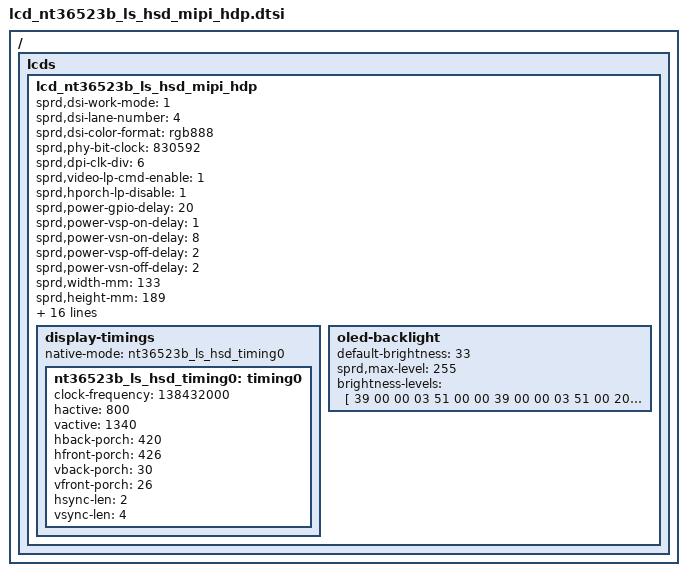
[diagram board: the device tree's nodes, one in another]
/**
*Name：<lcd_nt36523b_ls_hsd_mipi_hdp>
*Author：<huangzhongjie>
*Date：<2022/01/12>
*Purpose：<Tab A7 T168 LCD bring up>
*/
/ {
    fragment {
        target-path = "/";
        __overlay__ {
            lcds {
                lcd_nt36523b_ls_hsd_mipi_hdp: lcd_nt36523b_ls_hsd_mipi_hdp {

                    sprd,dsi-work-mode = <1>; /* video burst mode*/
                    sprd,dsi-lane-number = <4>;
                    sprd,dsi-color-format = "rgb888";

                    sprd,phy-bit-clock = <830592>;    /* kbps */
                    sprd,dpi-clk-div = <6>;
                    sprd,video-lp-cmd-enable = <1>;
                    sprd,hporch-lp-disable = <1>;
                    sprd,power-gpio-delay = <20>;/* ms */
                    sprd,power-vsp-on-delay = <1>;
                    sprd,power-vsn-on-delay = <8>;
                    sprd,power-vsp-off-delay = <2>;
                    sprd,power-vsn-off-delay = <2>;

                    sprd,width-mm = <133>;
                    sprd,height-mm = <189>;

                    sprd,reset-on-sequence = <1 10>, <0 5>, <1 5>, <0 5>, <1 10>;
                    sprd,reset-off-sequence = <1 5>;

                    sprd,esd-check-enable = <1>;
                    sprd,esd-check-mode = <0>;
                    sprd,esd-check-reg-count = <2>;
                    sprd,esd-check-register = [0A AB];
                    sprd,esd-check-value-len = <1 2>;
                    sprd,esd-check-value = [9C 00 00];
                    sprd,esd-check-period = <2000>;

                    sprd,initial-command = [
                        39 00 00 02 FF 20
                        39 00 00 02 FB 01
                        39 00 00 02 05 B1
                        39 00 00 02 06 C0
                        39 00 00 02 07 69
                        39 00 00 02 08 37
                        39 00 00 02 0D 63
                        39 00 00 02 0E 87
                        39 00 00 02 0F 55
                        39 00 00 02 58 60
                        39 00 00 02 69 90
                        39 00 00 02 75 30
                        39 00 00 02 77 B3
                        39 00 00 02 94 C0
                        39 00 00 02 95 09
                        39 00 00 02 96 09
                        39 00 00 02 FF 20
                        39 00 00 02 FB 01
                        39 00 00 11 B0 00 65 00 73 00 8E 00 A5 00 B9 00 CC 00 DD 00 EC
                        39 00 00 11 B1 00 FB 01 2C 01 51 01 8F 01 BB 02 05 02 3E 02 3F
                        39 00 00 11 B2 02 78 02 BB 02 EB 03 23 03 48 03 73 03 81 03 8F
                        39 00 00 0D B3 03 9E 03 AE 03 BD 03 CA 03 D1 03 D2
                        39 00 00 11 B4 00 65 00 73 00 8E 00 A5 00 B9 00 CC 00 DD 00 EC
                        39 00 00 11 B5 00 FB 01 2C 01 51 01 8F 01 BB 02 05 02 3E 02 3F
                        39 00 00 11 B6 02 78 02 BB 02 EB 03 23 03 48 03 73 03 81 03 8F
                        39 00 00 0D B7 03 9E 03 AE 03 BD 03 CA 03 D1 03 D2
                        39 00 00 11 B8 00 65 00 73 00 8E 00 A5 00 B9 00 CC 00 DD 00 EC
                        39 00 00 11 B9 00 FB 01 2C 01 51 01 8F 01 BB 02 05 02 3E 02 3F
                        39 00 00 11 BA 02 78 02 BB 02 EB 03 23 03 48 03 73 03 81 03 8F
                        39 00 00 0D BB 03 9E 03 AE 03 BD 03 CA 03 D1 03 D2
                        39 00 00 02 FF 21
                        39 00 00 02 FB 01
                        39 00 00 11 B0 00 5D 00 6B 00 86 00 9D 00 B1 00 C4 00 D5 00 E4
                        39 00 00 11 B1 00 F3 01 24 01 49 01 87 01 B3 01 FD 02 36 02 37
                        39 00 00 11 B2 02 70 02 B3 02 E3 03 1B 03 40 03 6B 03 79 03 87
                        39 00 00 0D B3 03 96 03 A6 03 B5 03 C2 03 C9 03 CA
                        39 00 00 11 B4 00 5D 00 6B 00 86 00 9D 00 B1 00 C4 00 D5 00 E4
                        39 00 00 11 B5 00 F3 01 24 01 49 01 87 01 B3 01 FD 02 36 02 37
                        39 00 00 11 B6 02 70 02 B3 02 E3 03 1B 03 40 03 6B 03 79 03 87
                        39 00 00 0D B7 03 96 03 A6 03 B5 03 C2 03 C9 03 CA
                        39 00 00 11 B8 00 5D 00 6B 00 86 00 9D 00 B1 00 C4 00 D5 00 E4
                        39 00 00 11 B9 00 F3 01 24 01 49 01 87 01 B3 01 FD 02 36 02 37
                        39 00 00 11 BA 02 70 02 B3 02 E3 03 1B 03 40 03 6B 03 79 03 87
                        39 00 00 0D BB 03 96 03 A6 03 B5 03 C2 03 C9 03 CA
                        39 00 00 02 FF 23
                        39 00 00 02 FB 01
                        39 00 00 02 00 80
                        39 00 00 02 07 00
                        39 00 00 02 08 02
                        39 00 00 02 09 00
                        39 00 00 02 11 00
                        39 00 00 02 12 A8
                        39 00 00 02 15 7D
                        39 00 00 02 16 0A
                        39 00 00 02 FF 24
                        39 00 00 02 FB 01
                        39 00 00 02 60 C8
                        39 00 00 02 61 3C
                        39 00 00 02 63 50
                        39 00 00 02 91 20
                        39 00 00 02 92 2F
                        39 00 00 02 93 1A
                        39 00 00 02 94 08
                        39 00 00 02 C2 CA
                        39 00 00 02 00 00
                        39 00 00 02 01 00
                        39 00 00 02 02 00
                        39 00 00 02 03 00
                        39 00 00 02 04 00
                        39 00 00 02 05 22
                        39 00 00 02 06 23
                        39 00 00 02 07 1C
                        39 00 00 02 08 1D
                        39 00 00 02 09 0C
                        39 00 00 02 0A 0D
                        39 00 00 02 0B 0E
                        39 00 00 02 0C 0F
                        39 00 00 02 0D 04
                        39 00 00 02 0E 05
                        39 00 00 02 0F 00
                        39 00 00 02 10 00
                        39 00 00 02 11 00
                        39 00 00 02 12 00
                        39 00 00 02 13 00
                        39 00 00 02 14 00
                        39 00 00 02 15 00
                        39 00 00 02 16 00
                        39 00 00 02 17 00
                        39 00 00 02 18 00
                        39 00 00 02 19 00
                        39 00 00 02 1A 00
                        39 00 00 02 1B 22
                        39 00 00 02 1C 23
                        39 00 00 02 1D 1C
                        39 00 00 02 1E 1D
                        39 00 00 02 1F 0C
                        39 00 00 02 20 0D
                        39 00 00 02 21 0E
                        39 00 00 02 22 0F
                        39 00 00 02 23 04
                        39 00 00 02 24 05
                        39 00 00 02 25 00
                        39 00 00 02 26 00
                        39 00 00 02 27 00
                        39 00 00 02 28 00
                        39 00 00 02 29 00
                        39 00 00 02 2A 00
                        39 00 00 02 2B 00
                        39 00 00 02 2F 02
                        39 00 00 02 30 41
                        39 00 00 02 33 41
                        39 00 00 02 34 02
                        39 00 00 02 37 22
                        39 00 00 02 39 01
                        39 00 00 02 3A 05
                        39 00 00 02 3B 2A
                        39 00 00 02 3D 52
                        39 00 00 02 AB 22
                        39 00 00 02 4D 21
                        39 00 00 02 4E 43
                        39 00 00 02 51 12
                        39 00 00 02 52 34
                        39 00 00 03 55 41 01
                        39 00 00 02 56 04
                        39 00 00 02 58 21
                        39 00 00 02 59 21
                        39 00 00 02 5A 05
                        39 00 00 02 5B 20
                        39 00 00 02 5C 00
                        39 00 00 02 5D 00
                        39 00 00 03 5E 00 00
                        39 00 00 02 5F 00
                        39 00 00 02 65 C2
                        39 00 00 02 7A 00
                        39 00 00 02 7B 00
                        39 00 00 02 7E 20
                        39 00 00 02 7F 3C
                        39 00 00 02 80 50
                        39 00 00 02 82 88
                        39 00 00 02 97 C2
                        39 00 00 02 C3 00
                        39 00 00 02 C4 20
                        39 00 00 02 DB F2
                        39 00 00 02 DC 2D
                        39 00 00 02 DF 82
                        39 00 00 02 E0 2D
                        39 00 00 02 E1 82
                        39 00 00 02 E2 2D
                        39 00 00 02 E3 82
                        39 00 00 02 E4 2D
                        39 00 00 02 E5 82
                        39 00 00 02 E6 2D
                        39 00 00 02 E7 00
                        39 00 00 02 E8 00
                        39 00 00 02 E9 82
                        39 00 00 02 EA 2D
                        39 00 00 02 EB 82
                        39 00 00 02 EE 2D
                        39 00 00 02 EF 82
                        39 00 00 02 F0 2D
                        39 00 00 02 B5 90
                        39 00 00 0D B6 05 00 05 00 00 00 00 00 05 05 00 00
                        39 00 00 02 FF 25
                        39 00 00 02 FB 01
                        39 00 00 02 05 04
                        39 00 00 02 13 04
                        39 00 00 02 14 77
                        39 00 00 02 19 07
                        39 00 00 02 1B 11
                        39 00 00 02 1E 00
                        39 00 00 02 1F 05
                        39 00 00 02 20 BB
                        39 00 00 02 25 04
                        39 00 00 02 26 05
                        39 00 00 02 27 20
                        39 00 00 02 3F 00
                        39 00 00 02 43 44
                        39 00 00 02 44 05
                        39 00 00 02 45 2A
                        39 00 00 02 48 05
                        39 00 00 02 49 20
                        39 00 00 02 5C 44
                        39 00 00 02 5D 05
                        39 00 00 02 5E 2A
                        39 00 00 02 61 05
                        39 00 00 02 62 20
                        39 00 00 02 FF 26
                        39 00 00 02 FB 01
                        39 00 00 02 00 A1
                        39 00 00 02 04 28
                        39 00 00 02 06 30
                        39 00 00 02 0C 11
                        39 00 00 02 0D 00
                        39 00 00 02 0F 09
                        39 00 00 02 11 00
                        39 00 00 02 12 50
                        39 00 00 02 13 49
                        39 00 00 02 14 49
                        39 00 00 02 15 00
                        39 00 00 02 16 90
                        39 00 00 02 17 A0
                        39 00 00 02 18 86
                        39 00 00 02 19 11
                        39 00 00 02 1A 00
                        39 00 00 02 1B 0E
                        39 00 00 02 1C E0
                        39 00 00 02 22 00
                        39 00 00 02 23 00
                        39 00 00 02 2A 0F
                        39 00 00 02 2B A0
                        39 00 00 02 1D C0
                        39 00 00 02 1E 2F
                        39 00 00 02 1F 2F
                        39 00 00 02 20 00
                        39 00 00 02 21 07
                        39 00 00 02 2F 86
                        39 00 00 02 30 2F
                        39 00 00 02 33 66
                        39 00 00 02 34 66
                        39 00 00 02 35 66
                        39 00 00 02 39 85
                        39 00 00 02 3A 2F
                        39 00 00 02 3B 00
                        39 00 00 02 C8 04
                        39 00 00 02 C9 15
                        39 00 00 02 CA 4E
                        39 00 00 02 CB 00
                        39 00 00 02 A9 63
                        39 00 00 02 AA 67
                        39 00 00 02 AB 6B
                        39 00 00 02 AC 59
                        39 00 00 02 AD 6E
                        39 00 00 02 AE 6A
                        39 00 00 02 AF 62
                        39 00 00 02 B0 5C
                        39 00 00 02 B1 69
                        39 00 00 02 B2 5E
                        39 00 00 02 B3 64
                        39 00 00 02 B4 68
                        39 00 00 02 B5 61
                        39 00 00 02 B6 58
                        39 00 00 02 B7 5B
                        39 00 00 02 B8 5F
                        39 00 00 02 B9 65
                        39 00 00 02 BA 66
                        39 00 00 02 BB 6C
                        39 00 00 02 BC 6D
                        39 00 00 02 FF 27
                        39 00 00 02 FB 01
                        39 00 00 02 00 00
                        39 00 00 02 C3 00
                        39 00 00 02 58 00
                        39 00 00 02 78 00
                        39 00 00 02 FF 2A
                        39 00 00 02 FB 01
                        39 00 00 02 64 16
                        39 00 00 02 6A 16
                        39 00 00 02 70 16
                        39 00 00 02 79 16
                        39 00 00 02 7C 16
                        39 00 00 02 97 3C
                        39 00 00 02 98 02
                        39 00 00 02 99 95
                        39 00 00 02 9A 06
                        39 00 00 02 9B 00
                        39 00 00 02 9C 0B
                        39 00 00 02 9D 0A
                        39 00 00 02 9E 90
                        39 00 00 02 A2 33
                        39 00 00 02 A3 F0
                        39 00 00 02 A4 C0
                        39 00 00 02 22 00
                        39 00 00 02 23 08
                        39 00 00 02 24 20
                        39 00 00 02 25 2F
                        39 00 00 02 26 F8
                        39 00 00 02 27 00
                        39 00 00 02 28 1A
                        39 00 00 02 29 00
                        39 00 00 02 2A 1A
                        39 00 00 02 2B 00
                        39 00 00 02 2D 1A
                        39 00 00 02 E8 00
                        39 00 00 02 FF F0
                        39 00 00 02 FB 01
                        39 00 00 02 3A 08
                        39 00 00 02 FF 24
                        39 00 00 02 FB 01
                        39 00 00 02 39 00
                        39 00 00 02 3A 03
                        39 00 00 02 3B B0
                        39 00 00 02 49 00
                        39 00 00 02 4A 03
                        39 00 00 02 4B B0
                        39 00 00 02 59 20
                        39 00 00 02 5A 03
                        39 00 00 02 5B AC
                        39 00 00 02 5C 00
                        39 00 00 02 5D 00
                        39 00 00 02 8D 00
                        39 00 00 02 8E 00
                        39 00 00 02 91 04
                        39 00 00 02 92 B2
                        39 00 00 02 DB 71
                        39 00 00 02 DC B1
                        39 00 00 02 DD 11
                        39 00 00 02 DE 27
                        39 00 00 02 DF 01
                        39 00 00 02 E0 B4
                        39 00 00 02 E1 01
                        39 00 00 02 E2 B4
                        39 00 00 02 E3 01
                        39 00 00 02 E4 B4
                        39 00 00 02 E5 01
                        39 00 00 02 E6 B4
                        39 00 00 02 EF 01
                        39 00 00 02 F0 B4
                        39 00 00 02 FF 25
                        39 00 00 02 FB 01
                        39 00 00 02 1E 00
                        39 00 00 02 1F 03
                        39 00 00 02 20 70
                        39 00 00 02 25 00
                        39 00 00 02 26 03
                        39 00 00 02 27 AC
                        39 00 00 02 32 00
                        39 00 00 02 33 03
                        39 00 00 02 34 AC
                        39 00 00 02 43 00
                        39 00 00 02 44 03
                        39 00 00 02 45 B2
                        39 00 00 02 46 03
                        39 00 00 02 47 B2
                        39 00 00 02 48 03
                        39 00 00 02 49 AC
                        39 00 00 02 5C 00
                        39 00 00 02 5D 03
                        39 00 00 02 5E B2
                        39 00 00 02 5F 03
                        39 00 00 02 60 B2
                        39 00 00 02 61 03
                        39 00 00 02 62 AC
                        39 00 00 02 FF 26
                        39 00 00 02 FB 01
                        39 00 00 02 02 31
                        39 00 00 02 19 0A
                        39 00 00 02 1A 33
                        39 00 00 02 1B 09
                        39 00 00 02 1C 13
                        39 00 00 02 2A 09
                        39 00 00 02 2B 60
                        39 00 00 02 1D 00
                        39 00 00 02 1E B5
                        39 00 00 02 1F B5
                        39 00 00 02 24 00
                        39 00 00 02 25 B5
                        39 00 00 02 2F 06
                        39 00 00 02 30 B5
                        39 00 00 02 31 06
                        39 00 00 02 32 CD
                        39 00 00 02 39 05
                        39 00 00 02 3A B5
                        39 00 00 02 FF 2A
                        39 00 00 02 FB 01
                        39 00 00 02 24 00
                        39 00 00 02 25 B2
                        39 00 00 02 FF 10
                        39 00 00 02 FB 01
                        39 00 00 06 3B 03 22 1A 04 04
                        39 00 00 03 68 04 01
                        39 00 00 03 51 00 00
                        39 00 00 02 53 2C
                        39 00 00 02 55 00
                        39 00 00 02 35 00
                        39 78 00 01 11
                        39 14 00 01 29
                    ];

                    sprd,sleep-in-command = [
                        39 00 00 02 FF 10
                        05 32 00 01 28
                        05 78 00 01 10
                    ];

                    sprd,sleep-out-command = [
                        23 64 00 23 11 00
                        23 05 00 23 29 00
                    ];


                    display-timings {
                        native-mode = <&nt36523b_ls_hsd_timing0>;
                        nt36523b_ls_hsd_timing0: timing0 {
                        clock-frequency = <138432000>;
                            hactive = <800>;
                            vactive = <1340>;
                            hback-porch = <420>;
                            hfront-porch = <426>;
                            vback-porch = <30>;
                            vfront-porch = <26>;
                            hsync-len = <2>;
                            vsync-len = <4>;
                        };
                    };

                    oled-backlight {
                        default-brightness = <33>;
                        sprd,max-level = <255>;

                        brightness-levels = [
                            39 00 00 03 51 00 00
                            39 00 00 03 51 00 20
                            39 00 00 03 51 00 30
                            39 00 00 03 51 00 40
                            39 00 00 03 51 00 50
                            39 00 00 03 51 00 60
                            39 00 00 03 51 00 70
                            39 00 00 03 51 00 80
                            39 00 00 03 51 00 90
                            39 00 00 03 51 00 A0
                            39 00 00 03 51 00 B0
                            39 00 00 03 51 00 C0
                            39 00 00 03 51 00 D0
                            39 00 00 03 51 00 E0
                            39 00 00 03 51 00 F0
                            39 00 00 03 51 01 00
                            39 00 00 03 51 01 11
                            39 00 00 03 51 01 21
                            39 00 00 03 51 01 31
                            39 00 00 03 51 01 41
                            39 00 00 03 51 01 51
                            39 00 00 03 51 01 61
                            39 00 00 03 51 01 71
                            39 00 00 03 51 01 81
                            39 00 00 03 51 01 91
                            39 00 00 03 51 01 A1
                            39 00 00 03 51 01 B1
                            39 00 00 03 51 01 C1
                            39 00 00 03 51 01 D1
                            39 00 00 03 51 01 E1
                            39 00 00 03 51 01 F1
                            39 00 00 03 51 02 01
                            39 00 00 03 51 02 11
                            39 00 00 03 51 02 22
                            39 00 00 03 51 02 32
                            39 00 00 03 51 02 42
                            39 00 00 03 51 02 52
                            39 00 00 03 51 02 62
                            39 00 00 03 51 02 72
                            39 00 00 03 51 02 82
                            39 00 00 03 51 02 92
                            39 00 00 03 51 02 A2
                            39 00 00 03 51 02 B2
                            39 00 00 03 51 02 C2
                            39 00 00 03 51 02 D2
                            39 00 00 03 51 02 E2
                            39 00 00 03 51 02 F2
                            39 00 00 03 51 03 02
                            39 00 00 03 51 03 12
                            39 00 00 03 51 03 22
                            39 00 00 03 51 03 32
                            39 00 00 03 51 03 43
                            39 00 00 03 51 03 53
                            39 00 00 03 51 03 63
                            39 00 00 03 51 03 73
                            39 00 00 03 51 03 83
                            39 00 00 03 51 03 93
                            39 00 00 03 51 03 A3
                            39 00 00 03 51 03 B3
                            39 00 00 03 51 03 C3
                            39 00 00 03 51 03 D3
                            39 00 00 03 51 03 E3
                            39 00 00 03 51 03 F3
                            39 00 00 03 51 04 03
                            39 00 00 03 51 04 13
                            39 00 00 03 51 04 23
                            39 00 00 03 51 04 33
                            39 00 00 03 51 04 43
                            39 00 00 03 51 04 54
                            39 00 00 03 51 04 64
                            39 00 00 03 51 04 74
                            39 00 00 03 51 04 84
                            39 00 00 03 51 04 94
                            39 00 00 03 51 04 A4
                            39 00 00 03 51 04 B4
                            39 00 00 03 51 04 C4
                            39 00 00 03 51 04 D4
                            39 00 00 03 51 04 E4
                            39 00 00 03 51 04 F4
                            39 00 00 03 51 05 04
                            39 00 00 03 51 05 14
                            39 00 00 03 51 05 24
                            39 00 00 03 51 05 34
                            39 00 00 03 51 05 44
                            39 00 00 03 51 05 54
                            39 00 00 03 51 05 65
                            39 00 00 03 51 05 75
                            39 00 00 03 51 05 85
                            39 00 00 03 51 05 95
                            39 00 00 03 51 05 A5
                            39 00 00 03 51 05 B5
                            39 00 00 03 51 05 C5
                            39 00 00 03 51 05 D5
                            39 00 00 03 51 05 E5
                            39 00 00 03 51 05 F5
                            39 00 00 03 51 06 05
                            39 00 00 03 51 06 15
                            39 00 00 03 51 06 25
                            39 00 00 03 51 06 35
                            39 00 00 03 51 06 45
                            39 00 00 03 51 06 55
                            39 00 00 03 51 06 65
                            39 00 00 03 51 06 76
                            39 00 00 03 51 06 86
                            39 00 00 03 51 06 96
                            39 00 00 03 51 06 A6
                            39 00 00 03 51 06 B6
                            39 00 00 03 51 06 C6
                            39 00 00 03 51 06 D6
                            39 00 00 03 51 06 E6
                            39 00 00 03 51 06 F6
                            39 00 00 03 51 07 06
                            39 00 00 03 51 07 16
                            39 00 00 03 51 07 26
                            39 00 00 03 51 07 36
                            39 00 00 03 51 07 46
                            39 00 00 03 51 07 56
                            39 00 00 03 51 07 66
                            39 00 00 03 51 07 76
                            39 00 00 03 51 07 87
                            39 00 00 03 51 07 97
                            39 00 00 03 51 07 A7
                            39 00 00 03 51 07 B7
                            39 00 00 03 51 07 C7
                            39 00 00 03 51 07 D7
                            39 00 00 03 51 07 E7
                            39 00 00 03 51 07 F7
                            39 00 00 03 51 08 07
                            39 00 00 03 51 08 17
                            39 00 00 03 51 08 27
                            39 00 00 03 51 08 37
                            39 00 00 03 51 08 47
                            39 00 00 03 51 08 57
                            39 00 00 03 51 08 67
                            39 00 00 03 51 08 77
                            39 00 00 03 51 08 87
                            39 00 00 03 51 08 98
                            39 00 00 03 51 08 A8
                            39 00 00 03 51 08 B8
                            39 00 00 03 51 08 C8
                            39 00 00 03 51 08 D8
                            39 00 00 03 51 08 E8
                            39 00 00 03 51 08 F8
                            39 00 00 03 51 09 08
                            39 00 00 03 51 09 18
                            39 00 00 03 51 09 28
                            39 00 00 03 51 09 38
                            39 00 00 03 51 09 48
                            39 00 00 03 51 09 58
                            39 00 00 03 51 09 68
                            39 00 00 03 51 09 78
                            39 00 00 03 51 09 88
                            39 00 00 03 51 09 98
                            39 00 00 03 51 09 A9
                            39 00 00 03 51 09 B9
                            39 00 00 03 51 09 C9
                            39 00 00 03 51 09 D9
                            39 00 00 03 51 09 E9
                            39 00 00 03 51 09 F9
                            39 00 00 03 51 0A 09
                            39 00 00 03 51 0A 19
                            39 00 00 03 51 0A 29
                            39 00 00 03 51 0A 39
                            39 00 00 03 51 0A 49
                            39 00 00 03 51 0A 59
                            39 00 00 03 51 0A 69
                            39 00 00 03 51 0A 79
                            39 00 00 03 51 0A 89
                            39 00 00 03 51 0A 99
                            39 00 00 03 51 0A A9
                            39 00 00 03 51 0A BA
                            39 00 00 03 51 0A CA
                            39 00 00 03 51 0A DA
                            39 00 00 03 51 0A EA
                            39 00 00 03 51 0A FA
                            39 00 00 03 51 0B 0A
                            39 00 00 03 51 0B 1A
                            39 00 00 03 51 0B 2A
                            39 00 00 03 51 0B 3A
                            39 00 00 03 51 0B 4A
                            39 00 00 03 51 0B 5A
                            39 00 00 03 51 0B 6A
                            39 00 00 03 51 0B 7A
                            39 00 00 03 51 0B 8A
                            39 00 00 03 51 0B 9A
                            39 00 00 03 51 0B AA
                            39 00 00 03 51 0B BA
                            39 00 00 03 51 0B CB
                            39 00 00 03 51 0B DB
                            39 00 00 03 51 0B EB
                            39 00 00 03 51 0B FB
                            39 00 00 03 51 0C 0B
                            39 00 00 03 51 0C 1B
                            39 00 00 03 51 0C 2B
                            39 00 00 03 51 0C 3B
                            39 00 00 03 51 0C 4B
                            39 00 00 03 51 0C 5B
                            39 00 00 03 51 0C 6B
                            39 00 00 03 51 0C 7B
                            39 00 00 03 51 0C 8B
                            39 00 00 03 51 0C 9B
                            39 00 00 03 51 0C AB
                            39 00 00 03 51 0C BB
                            39 00 00 03 51 0C CB
                            39 00 00 03 51 0C DC
                            39 00 00 03 51 0C EC
                            39 00 00 03 51 0C FC
                            39 00 00 03 51 0D 0C
                            39 00 00 03 51 0D 1C
                            39 00 00 03 51 0D 2C
                            39 00 00 03 51 0D 3C
                            39 00 00 03 51 0D 4C
                            39 00 00 03 51 0D 5C
                            39 00 00 03 51 0D 6C
                            39 00 00 03 51 0D 7C
                            39 00 00 03 51 0D 8C
                            39 00 00 03 51 0D 9C
                            39 00 00 03 51 0D AC
                            39 00 00 03 51 0D BC
                            39 00 00 03 51 0D CC
                            39 00 00 03 51 0D DC
                            39 00 00 03 51 0D ED
                            39 00 00 03 51 0D FD
                            39 00 00 03 51 0E 0D
                            39 00 00 03 51 0E 1D
                            39 00 00 03 51 0E 2D
                            39 00 00 03 51 0E 3D
                            39 00 00 03 51 0E 4D
                            39 00 00 03 51 0E 5D
                            39 00 00 03 51 0E 6D
                            39 00 00 03 51 0E 7D
                            39 00 00 03 51 0E 8D
                            39 00 00 03 51 0E 9D
                            39 00 00 03 51 0E AD
                            39 00 00 03 51 0E BD
                            39 00 00 03 51 0E CD
                            39 00 00 03 51 0E DD
                            39 00 00 03 51 0E ED
                            39 00 00 03 51 0E FE
                            39 00 00 03 51 0F 0E
                            39 00 00 03 51 0F 1E
                            39 00 00 03 51 0F 2E
                            39 00 00 03 51 0F 3E
                            39 00 00 03 51 0F 4E
                            39 00 00 03 51 0F 5E
                            39 00 00 03 51 0F 6E
                            39 00 00 03 51 0F 7E
                            39 00 00 03 51 0F 8E
                            39 00 00 03 51 0F 9E
                            39 00 00 03 51 0F AE
                            39 00 00 03 51 0F BE
                            39 00 00 03 51 0F CE
                            39 00 00 03 51 0F DE
                            39 00 00 03 51 0F EE
                            39 00 00 03 51 0F FE
                            39 00 00 03 51 0F FE
                        ];
                    };
                };
            };
        };
    };
};
